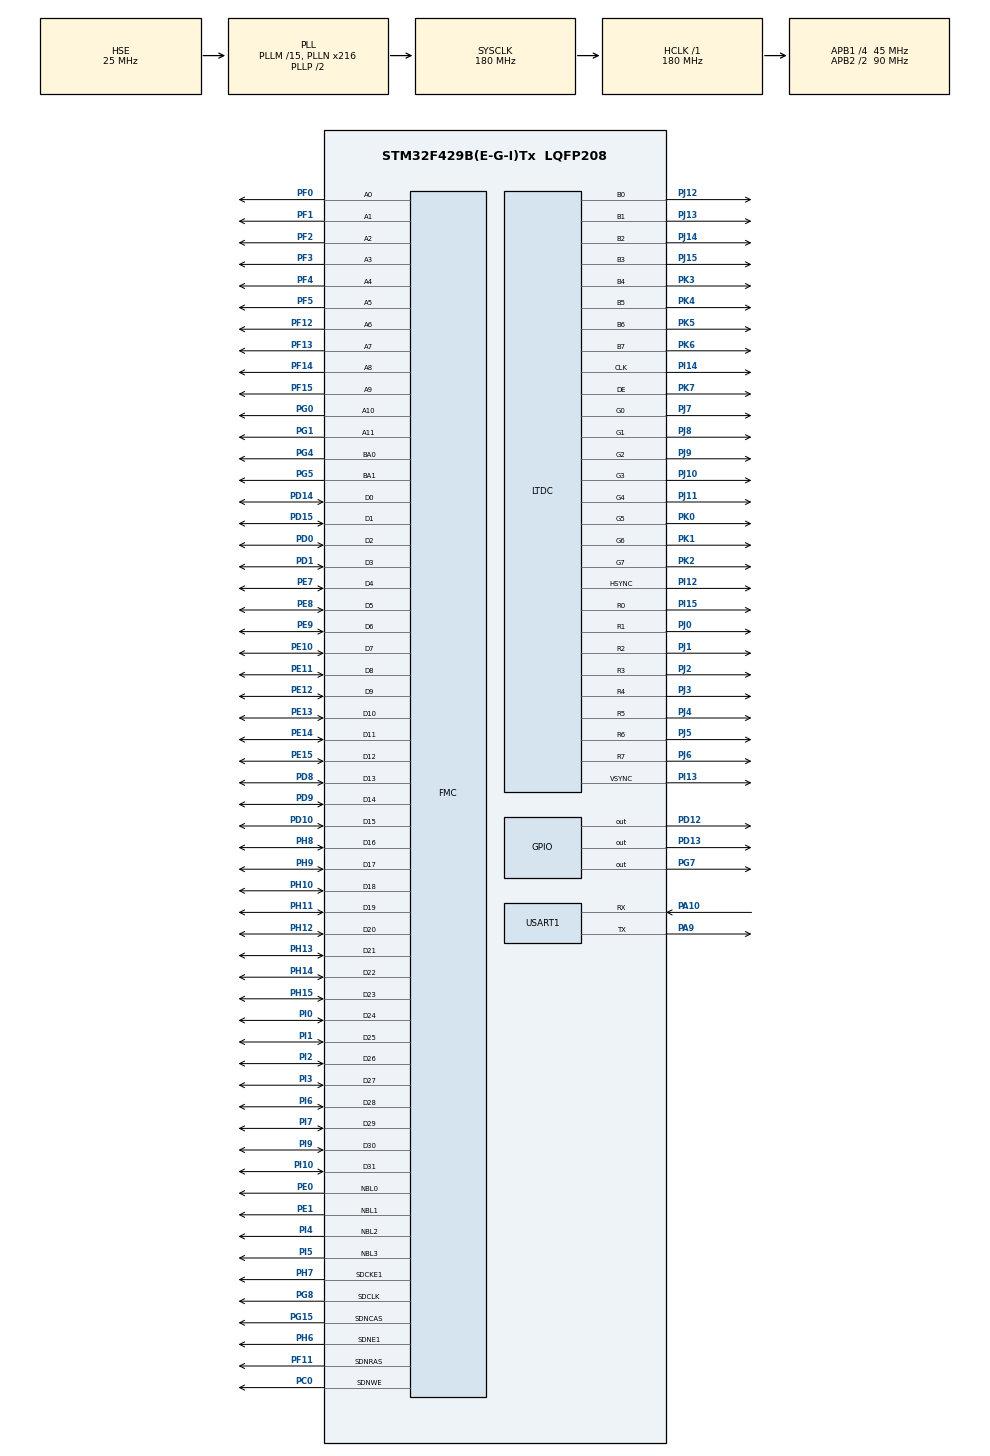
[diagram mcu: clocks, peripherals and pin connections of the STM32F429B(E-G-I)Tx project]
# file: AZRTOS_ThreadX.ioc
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FMC.CASLatency2=FMC_SDRAM_CAS_LATENCY_3
FMC.ExitSelfRefreshDelay2=7
FMC.LoadToActiveDelay2=2
FMC.RCDDelay2=2
FMC.RPDelay1=2
FMC.RPDelay2=2
FMC.ReadBurst1=FMC_SDRAM_RBURST_ENABLE
FMC.ReadBurst2=FMC_SDRAM_RBURST_ENABLE
FMC.ReadPipeDelay1=FMC_SDRAM_RPIPE_DELAY_1
FMC.ReadPipeDelay2=FMC_SDRAM_RPIPE_DELAY_1
FMC.RowCycleDelay1=6
FMC.RowCycleDelay2=6
FMC.SDClockPeriod1=FMC_SDRAM_CLOCK_PERIOD_2
FMC.SDClockPeriod2=FMC_SDRAM_CLOCK_PERIOD_2
FMC.SelfRefreshTime2=4
FMC.WriteRecoveryTime2=2
LTDC.ActiveH=272
LTDC.ActiveW=480
LTDC.Alpha0_L0=0
LTDC.Alpha_L0=255
LTDC.BlendingFactor1_L0=LTDC_BLENDING_FACTOR1_PAxCA
LTDC.BlendingFactor2_L0=LTDC_BLENDING_FACTOR2_PAxCA
LTDC.FBStartAdress_L0=0xD0000000
LTDC.Green=0
LTDC.Green_L0=0
LTDC.HBP=2
LTDC.HFP=2
LTDC.HSync=41
LTDC.ImageHeight_L0=272
LTDC.ImageWidth_L0=480
LTDC.Layers=0
LTDC.VSync=10
LTDC.WindowX1_L0=480
LTDC.WindowY1_L0=272
Mcu.Family=STM32F4
Mcu.Name=STM32F429B(E-G-I)Tx
Mcu.Package=LQFP208
NVIC.PriorityGroup=NVIC_PRIORITYGROUP_4
NVIC.TIM1_UP_TIM10_IRQn=true\:15\:0\:false\:false\:true\:false\:false\:true
NVIC.TimeBase=TIM1_UP_TIM10_IRQn
NVIC.TimeBaseIP=TIM1
NVIC.USART1_IRQn=true\:0\:0\:false\:false\:true\:false\:true\:true
PA10.Mode=Asynchronous
PA10.Signal=USART1_RX
PA9.Mode=Asynchronous
PA9.Signal=USART1_TX
PC0.Signal=FMC_SDNWE
PC14/OSC32_IN.Mode=LSE-External-Oscillator
PC14/OSC32_IN.Signal=RCC_OSC32_IN
PC15/OSC32_OUT.Mode=LSE-External-Oscillator
PC15/OSC32_OUT.Signal=RCC_OSC32_OUT
PD0.Signal=FMC_D2_DA2
PD1.Signal=FMC_D3_DA3
PD10.Signal=FMC_D15_DA15
PD12.Signal=GPIO_Output
PD13.Signal=GPIO_Output
PD14.Signal=FMC_D0_DA0
PD15.Signal=FMC_D1_DA1
PD8.Signal=FMC_D13_DA13
PD9.Signal=FMC_D14_DA14
PE0.Signal=FMC_NBL0
PE1.Signal=FMC_NBL1
PE10.Signal=FMC_D7_DA7
PE11.Signal=FMC_D8_DA8
PE12.Signal=FMC_D9_DA9
PE13.Signal=FMC_D10_DA10
PE14.Signal=FMC_D11_DA11
PE15.Signal=FMC_D12_DA12
PE7.Signal=FMC_D4_DA4
PE8.Signal=FMC_D5_DA5
PE9.Signal=FMC_D6_DA6
PF0.Signal=FMC_A0
PF1.Signal=FMC_A1
PF11.Signal=FMC_SDNRAS
PF12.Signal=FMC_A6
PF13.Signal=FMC_A7
PF14.Signal=FMC_A8
PF15.Signal=FMC_A9
PF2.Signal=FMC_A2
PF3.Signal=FMC_A3
PF4.Signal=FMC_A4
PF5.Signal=FMC_A5
PG0.Signal=FMC_A10
PG1.Signal=FMC_A11
PG15.Signal=FMC_SDNCAS
PG4.Signal=FMC_A14_BA0
PG5.Signal=FMC_A15_BA1
PG7.Signal=GPIO_Output
PG8.Signal=FMC_SDCLK
PH0/OSC_IN.Mode=HSE-External-Oscillator
PH0/OSC_IN.Signal=RCC_OSC_IN
PH1/OSC_OUT.Mode=HSE-External-Oscillator
PH1/OSC_OUT.Signal=RCC_OSC_OUT
PH10.Signal=FMC_D18
PH11.Signal=FMC_D19
PH12.Signal=FMC_D20
PH13.Signal=FMC_D21
PH14.Signal=FMC_D22
PH15.Signal=FMC_D23
PH6.Mode=SdramChipSelect2_2
PH6.Signal=FMC_SDNE1
PH7.Mode=SdramChipSelect2_2
PH7.Signal=FMC_SDCKE1
PH8.Signal=FMC_D16
PH9.Signal=FMC_D17
PI0.Signal=FMC_D24
PI1.Signal=FMC_D25
PI10.Signal=FMC_D31
PI12.GPIO_Speed=GPIO_SPEED_FREQ_MEDIUM
PI12.Mode=RGB888
PI12.Signal=LTDC_HSYNC
PI13.GPIO_Speed=GPIO_SPEED_FREQ_MEDIUM
PI13.Mode=RGB888
PI13.Signal=LTDC_VSYNC
PI14.GPIO_Speed=GPIO_SPEED_FREQ_MEDIUM
PI14.Mode=RGB888
PI14.Signal=LTDC_CLK
PI15.GPIO_Speed=GPIO_SPEED_FREQ_MEDIUM
PI15.Mode=RGB888
PI15.Signal=LTDC_R0
PI2.Signal=FMC_D26
PI3.Signal=FMC_D27
PI4.Signal=FMC_NBL2
PI5.Signal=FMC_NBL3
PI6.Signal=FMC_D28
PI7.Signal=FMC_D29
PI9.Signal=FMC_D30
PJ0.GPIO_Speed=GPIO_SPEED_FREQ_MEDIUM
PJ0.Mode=RGB888
PJ0.Signal=LTDC_R1
PJ1.GPIO_Speed=GPIO_SPEED_FREQ_MEDIUM
PJ1.Mode=RGB888
PJ1.Signal=LTDC_R2
PJ10.GPIO_Speed=GPIO_SPEED_FREQ_MEDIUM
PJ10.Mode=RGB888
PJ10.Signal=LTDC_G3
PJ11.GPIO_Speed=GPIO_SPEED_FREQ_MEDIUM
PJ11.Mode=RGB888
PJ11.Signal=LTDC_G4
PJ12.GPIO_Speed=GPIO_SPEED_FREQ_MEDIUM
PJ12.Mode=RGB888
PJ12.Signal=LTDC_B0
PJ13.GPIO_Speed=GPIO_SPEED_FREQ_MEDIUM
PJ13.Mode=RGB888
PJ13.Signal=LTDC_B1
PJ14.GPIO_Speed=GPIO_SPEED_FREQ_MEDIUM
PJ14.Mode=RGB888
PJ14.Signal=LTDC_B2
PJ15.GPIO_Speed=GPIO_SPEED_FREQ_MEDIUM
PJ15.Mode=RGB888
PJ15.Signal=LTDC_B3
PJ2.GPIO_Speed=GPIO_SPEED_FREQ_MEDIUM
PJ2.Mode=RGB888
PJ2.Signal=LTDC_R3
PJ3.GPIO_Speed=GPIO_SPEED_FREQ_MEDIUM
PJ3.Mode=RGB888
PJ3.Signal=LTDC_R4
PJ4.GPIO_Speed=GPIO_SPEED_FREQ_MEDIUM
PJ4.Mode=RGB888
PJ4.Signal=LTDC_R5
PJ5.GPIO_Speed=GPIO_SPEED_FREQ_MEDIUM
PJ5.Mode=RGB888
PJ5.Signal=LTDC_R6
PJ6.GPIO_Speed=GPIO_SPEED_FREQ_MEDIUM
PJ6.Mode=RGB888
PJ6.Signal=LTDC_R7
PJ7.GPIO_Speed=GPIO_SPEED_FREQ_MEDIUM
PJ7.Mode=RGB888
PJ7.Signal=LTDC_G0
PJ8.GPIO_Speed=GPIO_SPEED_FREQ_MEDIUM
PJ8.Mode=RGB888
PJ8.Signal=LTDC_G1
PJ9.GPIO_Speed=GPIO_SPEED_FREQ_MEDIUM
PJ9.Mode=RGB888
PJ9.Signal=LTDC_G2
PK0.GPIO_Speed=GPIO_SPEED_FREQ_MEDIUM
PK0.Mode=RGB888
PK0.Signal=LTDC_G5
PK1.GPIO_Speed=GPIO_SPEED_FREQ_MEDIUM
PK1.Mode=RGB888
PK1.Signal=LTDC_G6
PK2.GPIO_Speed=GPIO_SPEED_FREQ_MEDIUM
PK2.Mode=RGB888
PK2.Signal=LTDC_G7
PK3.GPIO_Speed=GPIO_SPEED_FREQ_MEDIUM
PK3.Mode=RGB888
PK3.Signal=LTDC_B4
PK4.GPIO_Speed=GPIO_SPEED_FREQ_MEDIUM
PK4.Mode=RGB888
PK4.Signal=LTDC_B5
PK5.GPIO_Speed=GPIO_SPEED_FREQ_MEDIUM
PK5.Mode=RGB888
PK5.Signal=LTDC_B6
PK6.GPIO_Speed=GPIO_SPEED_FREQ_MEDIUM
PK6.Mode=RGB888
PK6.Signal=LTDC_B7
PK7.GPIO_Speed=GPIO_SPEED_FREQ_MEDIUM
PK7.Mode=RGB888
PK7.Signal=LTDC_DE
ProjectManager.HeapSize=0x200
ProjectManager.StackSize=0x400
ProjectManager.TargetToolchain=MDK-ARM V5.32
RCC.48MHZClocksFreq_Value=90000000
RCC.AHBFreq_Value=180000000
RCC.APB1CLKDivider=RCC_HCLK_DIV4
RCC.APB1Freq_Value=45000000
RCC.APB1TimFreq_Value=90000000
RCC.APB2CLKDivider=RCC_HCLK_DIV2
RCC.APB2Freq_Value=90000000
RCC.APB2TimFreq_Value=180000000
RCC.CortexFreq_Value=180000000
RCC.HCLKFreq_Value=180000000
RCC.HSE_VALUE=25000000
RCC.HSI_VALUE=16000000
RCC.PLLM=15
RCC.PLLN=216
RCC.PLLSAIN=60
RCC.PLLSAIR=5
RCC.PLLSourceVirtual=RCC_PLLSOURCE_HSE
RCC.SYSCLKFreq_VALUE=180000000
RCC.SYSCLKSource=RCC_SYSCLKSOURCE_PLLCLK
RCC.VCOOutputFreq_Value=360000000
SH.FMC_A0.0=FMC_A0,12b-sda2
SH.FMC_A1.0=FMC_A1,12b-sda2
SH.FMC_A10.0=FMC_A10,12b-sda2
SH.FMC_A11.0=FMC_A11,12b-sda2
SH.FMC_A14_BA0.0=FMC_BA0,FourSdramBanks2
SH.FMC_A15_BA1.0=FMC_BA1,FourSdramBanks2
SH.FMC_A2.0=FMC_A2,12b-sda2
SH.FMC_A3.0=FMC_A3,12b-sda2
SH.FMC_A4.0=FMC_A4,12b-sda2
SH.FMC_A5.0=FMC_A5,12b-sda2
SH.FMC_A6.0=FMC_A6,12b-sda2
SH.FMC_A7.0=FMC_A7,12b-sda2
SH.FMC_A8.0=FMC_A8,12b-sda2
SH.FMC_A9.0=FMC_A9,12b-sda2
SH.FMC_D0_DA0.0=FMC_D0,sd-32b-d2
SH.FMC_D10_DA10.0=FMC_D10,sd-32b-d2
SH.FMC_D11_DA11.0=FMC_D11,sd-32b-d2
SH.FMC_D12_DA12.0=FMC_D12,sd-32b-d2
SH.FMC_D13_DA13.0=FMC_D13,sd-32b-d2
SH.FMC_D14_DA14.0=FMC_D14,sd-32b-d2
SH.FMC_D15_DA15.0=FMC_D15,sd-32b-d2
SH.FMC_D16.0=FMC_D16,sd-32b-d2
SH.FMC_D17.0=FMC_D17,sd-32b-d2
SH.FMC_D18.0=FMC_D18,sd-32b-d2
SH.FMC_D19.0=FMC_D19,sd-32b-d2
SH.FMC_D1_DA1.0=FMC_D1,sd-32b-d2
SH.FMC_D20.0=FMC_D20,sd-32b-d2
SH.FMC_D21.0=FMC_D21,sd-32b-d2
SH.FMC_D22.0=FMC_D22,sd-32b-d2
SH.FMC_D23.0=FMC_D23,sd-32b-d2
SH.FMC_D24.0=FMC_D24,sd-32b-d2
SH.FMC_D25.0=FMC_D25,sd-32b-d2
SH.FMC_D26.0=FMC_D26,sd-32b-d2
SH.FMC_D27.0=FMC_D27,sd-32b-d2
SH.FMC_D28.0=FMC_D28,sd-32b-d2
SH.FMC_D29.0=FMC_D29,sd-32b-d2
SH.FMC_D2_DA2.0=FMC_D2,sd-32b-d2
SH.FMC_D30.0=FMC_D30,sd-32b-d2
SH.FMC_D31.0=FMC_D31,sd-32b-d2
SH.FMC_D3_DA3.0=FMC_D3,sd-32b-d2
SH.FMC_D4_DA4.0=FMC_D4,sd-32b-d2
SH.FMC_D5_DA5.0=FMC_D5,sd-32b-d2
SH.FMC_D6_DA6.0=FMC_D6,sd-32b-d2
SH.FMC_D7_DA7.0=FMC_D7,sd-32b-d2
SH.FMC_D8_DA8.0=FMC_D8,sd-32b-d2
SH.FMC_D9_DA9.0=FMC_D9,sd-32b-d2
SH.FMC_NBL0.0=FMC_NBL0,Sd4ByteEnable2
SH.FMC_NBL1.0=FMC_NBL1,Sd4ByteEnable2
SH.FMC_NBL2.0=FMC_NBL2,Sd4ByteEnable2
SH.FMC_NBL3.0=FMC_NBL3,Sd4ByteEnable2
SH.FMC_SDCLK.0=FMC_SDCLK,12b-sda2
SH.FMC_SDNCAS.0=FMC_SDNCAS,12b-sda2
SH.FMC_SDNRAS.0=FMC_SDNRAS,12b-sda2
SH.FMC_SDNWE.0=FMC_SDNWE,12b-sda2
STMicroelectronics.X-CUBE-AZRTOS-F4.1.0.0.AZRTOS_APP_MEM_ALLOCATION_METHOD=0
STMicroelectronics.X-CUBE-AZRTOS-F4.1.0.0.ThreadXCcRTOSJjThreadXJjCore=true
STMicroelectronics.X-CUBE-AZRTOS-F4.1.0.0_IsAnAzureRtosMw=true
USART1.OverSampling=UART_OVERSAMPLING_8
USART1.VirtualMode=VM_ASYNC
VP_DMA2D_VS_DMA2D.Mode=DMA2D_Activate
VP_STMicroelectronics.X-CUBE-AZRTOS-F4_VS_RTOSJjThreadX_6.1.7_1.0.0.Mode=RTOSJjThreadX
VP_SYS_VS_tim1.Mode=TIM1
board=custom

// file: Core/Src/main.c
/* USER CODE BEGIN Header */
/**
  ******************************************************************************
  * @file           : main.c
  * @brief          : Main program body
  ******************************************************************************
  * @attention
  *
  * <h2><center>&copy; Copyright (c) 2021 STMicroelectronics.
  * All rights reserved.</center></h2>
  *
  * This software component is licensed by ST under Ultimate Liberty license
  * SLA0044, the "License"; You may not use this file except in compliance with
  * the License. You may obtain a copy of the License at:
  *                             www.st.com/SLA0044
  *
  ******************************************************************************
  */
/* USER CODE END Header */
#include "main.h"
#include "app_threadx.h"

/* USER CODE BEGIN Includes */
#include "SDRAM.h"
/* USER CODE END Includes */

DMA2D_HandleTypeDef hdma2d;

LTDC_HandleTypeDef hltdc;

UART_HandleTypeDef huart1;

SDRAM_HandleTypeDef hsdram2;

void SystemClock_Config(void);
static void MX_GPIO_Init(void);
static void MX_USART1_UART_Init(void);
static void MX_FMC_Init(void);
static void MX_LTDC_Init(void);
static void MX_DMA2D_Init(void);

int main(void)
{

  /* MCU Configuration--------------------------------------------------------*/

  /* Reset of all peripherals, Initializes the Flash interface and the Systick. */
  HAL_Init();

  /* Configure the system clock */
  SystemClock_Config();

  /* Initialize all configured peripherals */
  MX_GPIO_Init();
  MX_USART1_UART_Init();
  MX_FMC_Init();
  MX_LTDC_Init();
  MX_DMA2D_Init();
  /* USER CODE BEGIN 2 */
	HAL_GPIO_WritePin(GPIOD, GPIO_PIN_13, GPIO_PIN_SET);		//开启LCD背光

  /* USER CODE END 2 */

  MX_ThreadX_Init();
  /* Infinite loop */
  while (1)
  {

  }
}

void SystemClock_Config(void)
{
  RCC_OscInitTypeDef RCC_OscInitStruct = {0};
  RCC_ClkInitTypeDef RCC_ClkInitStruct = {0};

  /** Configure the main internal regulator output voltage
  */
  __HAL_RCC_PWR_CLK_ENABLE();
  __HAL_PWR_VOLTAGESCALING_CONFIG(PWR_REGULATOR_VOLTAGE_SCALE1);
  /** Initializes the RCC Oscillators according to the specified parameters
  * in the RCC_OscInitTypeDef structure.
  */
  RCC_OscInitStruct.OscillatorType = RCC_OSCILLATORTYPE_HSE;
  RCC_OscInitStruct.HSEState = RCC_HSE_ON;
  RCC_OscInitStruct.PLL.PLLState = RCC_PLL_ON;
  RCC_OscInitStruct.PLL.PLLSource = RCC_PLLSOURCE_HSE;
  RCC_OscInitStruct.PLL.PLLM = 15;
  RCC_OscInitStruct.PLL.PLLN = 216;
  RCC_OscInitStruct.PLL.PLLP = RCC_PLLP_DIV2;
  RCC_OscInitStruct.PLL.PLLQ = 4;
  if (HAL_RCC_OscConfig(&RCC_OscInitStruct) != HAL_OK)
  {
    Error_Handler();
  }
  /** Activate the Over-Drive mode
  */
  if (HAL_PWREx_EnableOverDrive() != HAL_OK)
  {
    Error_Handler();
  }
  /** Initializes the CPU, AHB and APB buses clocks
  */
  RCC_ClkInitStruct.ClockType = RCC_CLOCKTYPE_HCLK|RCC_CLOCKTYPE_SYSCLK
                              |RCC_CLOCKTYPE_PCLK1|RCC_CLOCKTYPE_PCLK2;
  RCC_ClkInitStruct.SYSCLKSource = RCC_SYSCLKSOURCE_PLLCLK;
  RCC_ClkInitStruct.AHBCLKDivider = RCC_SYSCLK_DIV1;
  RCC_ClkInitStruct.APB1CLKDivider = RCC_HCLK_DIV4;
  RCC_ClkInitStruct.APB2CLKDivider = RCC_HCLK_DIV2;

  if (HAL_RCC_ClockConfig(&RCC_ClkInitStruct, FLASH_LATENCY_5) != HAL_OK)
  {
    Error_Handler();
  }
}

static void MX_DMA2D_Init(void)
{

  hdma2d.Instance = DMA2D;
  hdma2d.Init.Mode = DMA2D_M2M;
  hdma2d.Init.ColorMode = DMA2D_OUTPUT_ARGB8888;
  hdma2d.Init.OutputOffset = 0;
  hdma2d.LayerCfg[1].InputOffset = 0;
  hdma2d.LayerCfg[1].InputColorMode = DMA2D_INPUT_ARGB8888;
  hdma2d.LayerCfg[1].AlphaMode = DMA2D_NO_MODIF_ALPHA;
  hdma2d.LayerCfg[1].InputAlpha = 0;
  if (HAL_DMA2D_Init(&hdma2d) != HAL_OK)
  {
    Error_Handler();
  }
  if (HAL_DMA2D_ConfigLayer(&hdma2d, 1) != HAL_OK)
  {
    Error_Handler();
  }

}

static void MX_LTDC_Init(void)
{

  LTDC_LayerCfgTypeDef pLayerCfg = {0};

  hltdc.Instance = LTDC;
  hltdc.Init.HSPolarity = LTDC_HSPOLARITY_AL;
  hltdc.Init.VSPolarity = LTDC_VSPOLARITY_AL;
  hltdc.Init.DEPolarity = LTDC_DEPOLARITY_AL;
  hltdc.Init.PCPolarity = LTDC_PCPOLARITY_IPC;
  hltdc.Init.HorizontalSync = 40;
  hltdc.Init.VerticalSync = 9;
  hltdc.Init.AccumulatedHBP = 42;
  hltdc.Init.AccumulatedVBP = 11;
  hltdc.Init.AccumulatedActiveW = 522;
  hltdc.Init.AccumulatedActiveH = 283;
  hltdc.Init.TotalWidth = 524;
  hltdc.Init.TotalHeigh = 285;
  hltdc.Init.Backcolor.Blue = 0;
  hltdc.Init.Backcolor.Green = 0;
  hltdc.Init.Backcolor.Red = 0;
  if (HAL_LTDC_Init(&hltdc) != HAL_OK)
  {
    Error_Handler();
  }
  pLayerCfg.WindowX0 = 0;
  pLayerCfg.WindowX1 = 480;
  pLayerCfg.WindowY0 = 0;
  pLayerCfg.WindowY1 = 272;
  pLayerCfg.PixelFormat = LTDC_PIXEL_FORMAT_ARGB8888;
  pLayerCfg.Alpha = 255;
  pLayerCfg.Alpha0 = 0;
  pLayerCfg.BlendingFactor1 = LTDC_BLENDING_FACTOR1_PAxCA;
  pLayerCfg.BlendingFactor2 = LTDC_BLENDING_FACTOR2_PAxCA;
  pLayerCfg.FBStartAdress = 0xD0000000;
  pLayerCfg.ImageWidth = 480;
  pLayerCfg.ImageHeight = 272;
  pLayerCfg.Backcolor.Blue = 0;
  pLayerCfg.Backcolor.Green = 0;
  pLayerCfg.Backcolor.Red = 0;
  if (HAL_LTDC_ConfigLayer(&hltdc, &pLayerCfg, 0) != HAL_OK)
  {
    Error_Handler();
  }

}

static void MX_USART1_UART_Init(void)
{

  huart1.Instance = USART1;
  huart1.Init.BaudRate = 115200;
  huart1.Init.WordLength = UART_WORDLENGTH_8B;
  huart1.Init.StopBits = UART_STOPBITS_1;
  huart1.Init.Parity = UART_PARITY_NONE;
  huart1.Init.Mode = UART_MODE_TX_RX;
  huart1.Init.HwFlowCtl = UART_HWCONTROL_NONE;
  huart1.Init.OverSampling = UART_OVERSAMPLING_8;
  if (HAL_UART_Init(&huart1) != HAL_OK)
  {
    Error_Handler();
  }

}

/* FMC initialization function */
static void MX_FMC_Init(void)
{

  FMC_SDRAM_TimingTypeDef SdramTiming = {0};

  /** Perform the SDRAM2 memory initialization sequence
  */
  hsdram2.Instance = FMC_SDRAM_DEVICE;
  /* hsdram2.Init */
  hsdram2.Init.SDBank = FMC_SDRAM_BANK2;
  hsdram2.Init.ColumnBitsNumber = FMC_SDRAM_COLUMN_BITS_NUM_8;
  hsdram2.Init.RowBitsNumber = FMC_SDRAM_ROW_BITS_NUM_12;
  hsdram2.Init.MemoryDataWidth = FMC_SDRAM_MEM_BUS_WIDTH_32;
  hsdram2.Init.InternalBankNumber = FMC_SDRAM_INTERN_BANKS_NUM_4;
  hsdram2.Init.CASLatency = FMC_SDRAM_CAS_LATENCY_3;
  hsdram2.Init.WriteProtection = FMC_SDRAM_WRITE_PROTECTION_DISABLE;
  hsdram2.Init.SDClockPeriod = FMC_SDRAM_CLOCK_PERIOD_2;
  hsdram2.Init.ReadBurst = FMC_SDRAM_RBURST_ENABLE;
  hsdram2.Init.ReadPipeDelay = FMC_SDRAM_RPIPE_DELAY_1;
  /* SdramTiming */
  SdramTiming.LoadToActiveDelay = 2;
  SdramTiming.ExitSelfRefreshDelay = 7;
  SdramTiming.SelfRefreshTime = 4;
  SdramTiming.RowCycleDelay = 6;
  SdramTiming.WriteRecoveryTime = 2;
  SdramTiming.RPDelay = 2;
  SdramTiming.RCDDelay = 2;

  if (HAL_SDRAM_Init(&hsdram2, &SdramTiming) != HAL_OK)
  {
    Error_Handler( );
  }

  /* USER CODE BEGIN FMC_Init 2 */
	FMC_SDRAM_CommandTypeDef command;
	SDRAM_Initialization_Sequence(&hsdram2, &command);
  /* USER CODE END FMC_Init 2 */
}

static void MX_GPIO_Init(void)
{
  GPIO_InitTypeDef GPIO_InitStruct = {0};

  /* GPIO Ports Clock Enable */
  __HAL_RCC_GPIOC_CLK_ENABLE();
  __HAL_RCC_GPIOI_CLK_ENABLE();
  __HAL_RCC_GPIOF_CLK_ENABLE();
  __HAL_RCC_GPIOH_CLK_ENABLE();
  __HAL_RCC_GPIOJ_CLK_ENABLE();
  __HAL_RCC_GPIOG_CLK_ENABLE();
  __HAL_RCC_GPIOE_CLK_ENABLE();
  __HAL_RCC_GPIOD_CLK_ENABLE();
  __HAL_RCC_GPIOK_CLK_ENABLE();
  __HAL_RCC_GPIOA_CLK_ENABLE();

  /*Configure GPIO pin Output Level */
  HAL_GPIO_WritePin(GPIOD, GPIO_PIN_12|GPIO_PIN_13, GPIO_PIN_RESET);

  /*Configure GPIO pin Output Level */
  HAL_GPIO_WritePin(GPIOG, GPIO_PIN_7, GPIO_PIN_RESET);

  /*Configure GPIO pins : PD12 PD13 */
  GPIO_InitStruct.Pin = GPIO_PIN_12|GPIO_PIN_13;
  GPIO_InitStruct.Mode = GPIO_MODE_OUTPUT_PP;
  GPIO_InitStruct.Pull = GPIO_NOPULL;
  GPIO_InitStruct.Speed = GPIO_SPEED_FREQ_LOW;
  HAL_GPIO_Init(GPIOD, &GPIO_InitStruct);

  /*Configure GPIO pin : PG7 */
  GPIO_InitStruct.Pin = GPIO_PIN_7;
  GPIO_InitStruct.Mode = GPIO_MODE_OUTPUT_PP;
  GPIO_InitStruct.Pull = GPIO_NOPULL;
  GPIO_InitStruct.Speed = GPIO_SPEED_FREQ_LOW;
  HAL_GPIO_Init(GPIOG, &GPIO_InitStruct);

}

void HAL_TIM_PeriodElapsedCallback(TIM_HandleTypeDef *htim)
{
  if (htim->Instance == TIM1) {
    HAL_IncTick();
  }
}

void Error_Handler(void)
{
  __disable_irq();
  while (1)
  {
  }
}

/************************ (C) COPYRIGHT STMicroelectronics *****END OF FILE****/
